AUTOSAR XML (schema 3.1.2)
package /Components/SWC_EngLim
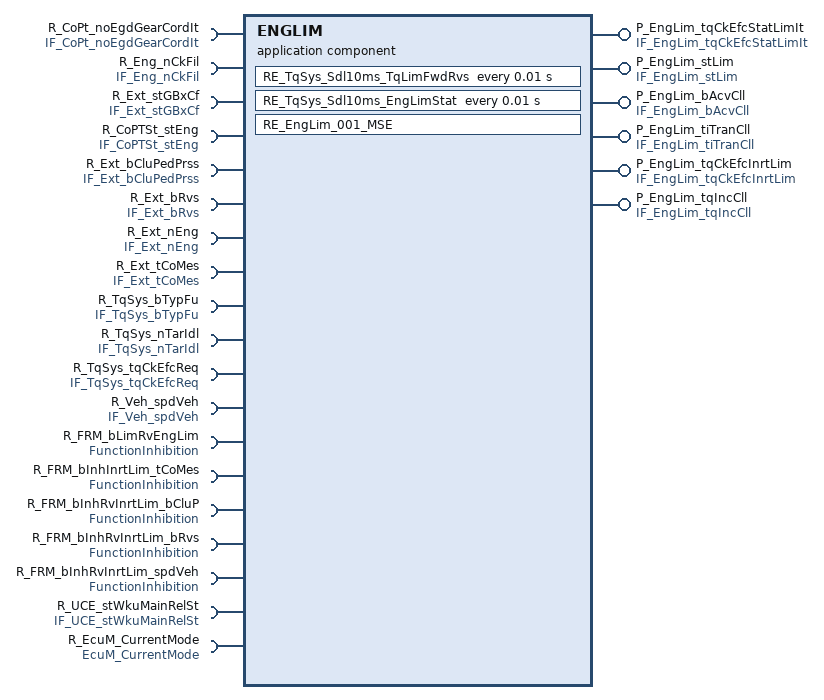
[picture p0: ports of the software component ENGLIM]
  application software component type ENGLIM
    17 x require port:
      R_CoPt_noEgdGearCordIt: unqueued-receiver-com-spec{data-element=CoPt_noEgdGearCordIt, init-value=ConstantValue, resync-time=0}, required-interface=IF_CoPt_noEgdGearCordIt
      R_Eng_nCkFil: unqueued-receiver-com-spec{data-element=Eng_nCkFil, init-value=ConstantValue1, resync-time=0}, required-interface=IF_Eng_nCkFil
      R_Ext_stGBxCf: unqueued-receiver-com-spec{data-element=Ext_stGBxCf, init-value=ConstantValue3, resync-time=0}, required-interface=IF_Ext_stGBxCf
      R_CoPTSt_stEng: unqueued-receiver-com-spec{data-element=CoPTSt_stEng, init-value=ConstantValue5, resync-time=0}, required-interface=IF_CoPTSt_stEng
      R_Ext_bCluPedPrss: unqueued-receiver-com-spec{data-element=Ext_bCluPedPrss, init-value=ConstantValue7, resync-time=0}, required-interface=IF_Ext_bCluPedPrss
      R_Ext_bRvs: unqueued-receiver-com-spec{data-element=Ext_bRvs, init-value=ConstantValue9, resync-time=0}, required-interface=IF_Ext_bRvs
      R_Ext_nEng: unqueued-receiver-com-spec{data-element=Ext_nEng, init-value=ConstantValue11, resync-time=0}, required-interface=IF_Ext_nEng
      R_Ext_tCoMes: unqueued-receiver-com-spec{data-element=Ext_tCoMes, init-value=ConstantValue13, resync-time=0}, required-interface=IF_Ext_tCoMes
      R_TqSys_bTypFu: unqueued-receiver-com-spec{data-element=TqSys_bTypFu, init-value=ConstantValue15, resync-time=0}, required-interface=IF_TqSys_bTypFu
      R_TqSys_nTarIdl: unqueued-receiver-com-spec{data-element=TqSys_nTarIdl, init-value=ConstantValue17, resync-time=0}, required-interface=IF_TqSys_nTarIdl
      R_TqSys_tqCkEfcReq: unqueued-receiver-com-spec{data-element=TqSys_tqCkEfcReq, init-value=ConstantValue19, resync-time=0}, required-interface=IF_TqSys_tqCkEfcReq
      R_Veh_spdVeh: unqueued-receiver-com-spec{data-element=Veh_spdVeh, init-value=ConstantValue21, resync-time=0}, required-interface=IF_Veh_spdVeh
      R_FRM_bLimRvEngLim: required-interface=FunctionInhibition
      R_FRM_bInhInrtLim_tCoMes: required-interface=FunctionInhibition
      R_FRM_bInhRvInrtLim_bCluP: required-interface=FunctionInhibition
      R_FRM_bInhRvInrtLim_bRvs: required-interface=FunctionInhibition
      R_FRM_bInhRvInrtLim_spdVeh: required-interface=FunctionInhibition
    6 x provide port:
      P_EngLim_tqCkEfcStatLimIt: unqueued-sender-com-spec{data-element=EngLim_tqCkEfcStatLimIt, can-invalidate=false, init-value=ConstantValue23}, provided-interface=IF_EngLim_tqCkEfcStatLimIt
      P_EngLim_stLim: unqueued-sender-com-spec{data-element=EngLim_stLim, can-invalidate=false, init-value=EngLim_stLim_out}, provided-interface=IF_EngLim_stLim
      P_EngLim_bAcvCll: unqueued-sender-com-spec{data-element=EngLim_bAcvCll, can-invalidate=false, init-value=ConstantValue25}, provided-interface=IF_EngLim_bAcvCll
      P_EngLim_tiTranCll: unqueued-sender-com-spec{data-element=EngLim_tiTranCll, can-invalidate=false, init-value=ConstantValue27}, provided-interface=IF_EngLim_tiTranCll
      P_EngLim_tqCkEfcInrtLim: unqueued-sender-com-spec{data-element=EngLim_tqCkEfcInrtLim, can-invalidate=false, init-value=EngLim_tqCkEfcInrtLim_out}, provided-interface=IF_EngLim_tqCkEfcInrtLim
      P_EngLim_tqIncCll: unqueued-sender-com-spec{data-element=EngLim_tqIncCll, can-invalidate=false, init-value=ConstantValue29}, provided-interface=IF_EngLim_tqIncCll
    require port R_UCE_stWkuMainRelSt: required-interface=IF_UCE_stWkuMainRelSt
    require port R_EcuM_CurrentMode: required-interface=EcuM_CurrentMode
  18 x constant specification:
    ConstantValue
      value:
        integer literal ConstantValue: type=DT_CoPt_noEgdGearCordIt, value=0
    ConstantValue1
      value:
        integer literal ConstantValue1: type=DT_Eng_nCkFil, value=0
    ConstantValue11
      value:
        integer literal ConstantValue11: type=DT_Ext_nEng, value=0
    ConstantValue13
      value:
        integer literal ConstantValue13: type=DT_Ext_tCoMes, value=20
    ConstantValue15
      value:
        boolean literal ConstantValue15: type=DT_TqSys_bTypFu, value=false
    ConstantValue17
      value:
        integer literal ConstantValue17: type=DT_TqSys_nTarIdl, value=0
    ConstantValue19
      value:
        integer literal ConstantValue19: type=DT_TqSys_tqCkEfcReq, value=0
    ConstantValue21
      value:
        integer literal ConstantValue21: type=DT_Veh_spdVeh, value=0
    ConstantValue23
      value:
        integer literal ConstantValue23: type=DT_EngLim_tqCkEfcStatLimIt, value=0
    ConstantValue25
      value:
        boolean literal ConstantValue25: type=DT_EngLim_bAcvCll, value=false
    ConstantValue27
      value:
        integer literal ConstantValue27: type=DT_EngLim_tiTranCll, value=0
    ConstantValue29
      value:
        integer literal ConstantValue29: type=DT_EngLim_tqIncCll, value=0
    ConstantValue3
      value:
        integer literal ConstantValue3: type=DT_Ext_stGBxCf, value=0
    ConstantValue5
      value:
        integer literal ConstantValue5: type=DT_CoPTSt_stEng, value=1
    ConstantValue7
      value:
        boolean literal ConstantValue7: type=DT_Ext_bCluPedPrss, value=false
    ConstantValue9
      value:
        boolean literal ConstantValue9: type=DT_Ext_bRvs, value=false
    EngLim_stLim_out
      value:
        integer literal EngLim_stLim_out: type=DT_EngLim_stLim, value=1
    EngLim_tqCkEfcInrtLim_out
      value:
        integer literal EngLim_tqCkEfcInrtLim_out: type=DT_EngLim_tqCkEfcInrtLim, value=32000
  internal behavior IB_EngLim: component=ENGLIM
    mode switch event EV_EngLim_001_MSE: start-on-event=RE_EngLim_001_MSE, activation=ENTRY, mode=R_EcuM_CurrentMode.currentMode.RUN
    timing event EV_TqSys_Sdl10ms_TqLimFwdRvs: mode-dependency=dependent-on-mode=R_UCE_stWkuMainRelSt.RCD_stWkuMainRelSt.Invalid, start-on-event=RE_TqSys_Sdl10ms_TqLimFwdRvs, period=0.01
    timing event EV_TqSys_Sdl10ms_EngLimStat: mode-dependency=dependent-on-mode=R_UCE_stWkuMainRelSt.RCD_stWkuMainRelSt.Invalid, start-on-event=RE_TqSys_Sdl10ms_EngLimStat, period=0.01
    runnable RE_EngLim_001_MSE
      6 x data send point:
        ds_EngLim_tqCkEfcStatLimIt: data-element=P_EngLim_tqCkEfcStatLimIt.EngLim_tqCkEfcStatLimIt
        ds_EngLim_tqCkEfcInrtLim: data-element=P_EngLim_tqCkEfcInrtLim.EngLim_tqCkEfcInrtLim
        ds_EngLim_tiTranCll: data-element=P_EngLim_tiTranCll.EngLim_tiTranCll
        ds_EngLim_bAcvCll: data-element=P_EngLim_bAcvCll.EngLim_bAcvCll
        ds_EngLim_tqIncCll: data-element=P_EngLim_tqIncCll.EngLim_tqIncCll
        ds_EngLim_stLim: data-element=P_EngLim_stLim.EngLim_stLim
    runnable RE_TqSys_Sdl10ms_EngLimStat
      data receive point dr_CoPt_noEgdGearCordIt: data-element=R_CoPt_noEgdGearCordIt.CoPt_noEgdGearCordIt
      data receive point dr_Eng_nCkFil: data-element=R_Eng_nCkFil.Eng_nCkFil
      data receive point dr_Ext_stGBxCf: data-element=R_Ext_stGBxCf.Ext_stGBxCf
      data send point ds_EngLim_tqCkEfcStatLimIt: data-element=P_EngLim_tqCkEfcStatLimIt.EngLim_tqCkEfcStatLimIt
      sync call sc_FRM_bLimRvEngLim: operation=R_FRM_bLimRvEngLim.GetFunctionPermission
    runnable RE_TqSys_Sdl10ms_TqLimFwdRvs
      9 x data receive point:
        dr_Ext_nEng: data-element=R_Ext_nEng.Ext_nEng
        dr_TqSys_tqCkEfcReq: data-element=R_TqSys_tqCkEfcReq.TqSys_tqCkEfcReq
        dr_Ext_tCoMes: data-element=R_Ext_tCoMes.Ext_tCoMes
        dr_Ext_bRvs: data-element=R_Ext_bRvs.Ext_bRvs
        dr_Ext_bCluPedPrss: data-element=R_Ext_bCluPedPrss.Ext_bCluPedPrss
        dr_Veh_spdVeh: data-element=R_Veh_spdVeh.Veh_spdVeh
        dr_TqSys_bTypFu: data-element=R_TqSys_bTypFu.TqSys_bTypFu
        dr_CoPTSt_stEng: data-element=R_CoPTSt_stEng.CoPTSt_stEng
        dr_TqSys_nTarIdl: data-element=R_TqSys_nTarIdl.TqSys_nTarIdl
      5 x data send point:
        ds_EngLim_stLim: data-element=P_EngLim_stLim.EngLim_stLim
        ds_EngLim_tiTranCll: data-element=P_EngLim_tiTranCll.EngLim_tiTranCll
        ds_EngLim_tqIncCll: data-element=P_EngLim_tqIncCll.EngLim_tqIncCll
        ds_EngLim_tqCkEfcInrtLim: data-element=P_EngLim_tqCkEfcInrtLim.EngLim_tqCkEfcInrtLim
        ds_EngLim_bAcvCll: data-element=P_EngLim_bAcvCll.EngLim_bAcvCll
      4 x sync call:
        sc_FRM_bInhRvInrtLim_spdVeh: operation=R_FRM_bInhRvInrtLim_spdVeh.GetFunctionPermission
        sc_FRM_bInhRvInrtLim_bCluP: operation=R_FRM_bInhRvInrtLim_bCluP.GetFunctionPermission
        sc_FRM_bInhInrtLim_tCoMes: operation=R_FRM_bInhInrtLim_tCoMes.GetFunctionPermission
        sc_FRM_bInhRvInrtLim_bRvs: operation=R_FRM_bInhRvInrtLim_bRvs.GetFunctionPermission
  swc implementation Imp_EngLim: programming-language=C, behavior=IB_EngLim
    code-descriptors:
      code CodeDescriptor: type=SRC
        9 x xfile:
          EngLim_h: url=EngLim.h
          EngLim_c: url=EngLim.c
          EngLim_calibrations_h: url=EngLim_calibrations.h
          TqSys_Sdl10ms_TqLimFwdRvs_fct_h: url=TqSys_Sdl10ms_TqLimFwdRvs_fct.h
          TqSys_Sdl10ms_EngLimStat_fct_h: url=TqSys_Sdl10ms_EngLimStat_fct.h
          TqSys_Sdl10ms_TqLimFwdRvs_fct_c: url=TqSys_Sdl10ms_TqLimFwdRvs_fct.c
          EngLim_calibrations_c: url=EngLim_calibrations.c
          TqSys_Sdl10ms_EngLimStat_fct_c: url=TqSys_Sdl10ms_EngLimStat_fct.c
          EngLim_MemMap_h: url=EngLim_MemMap.h
